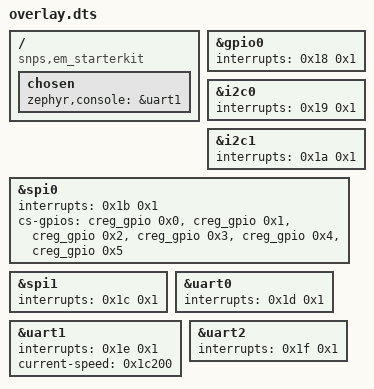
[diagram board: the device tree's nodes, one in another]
/ {
	compatible = "snps,em_starterkit", "snps,em_starterkit-em9d";
	chosen {
		zephyr,console = &uart1;
	};
};
&gpio0{
	interrupts = < 0x18 0x1 >;
};
&i2c0{
	interrupts = < 0x19 0x1 >;
};
&i2c1{
	interrupts = < 0x1a 0x1 >;
};
&spi0{
	interrupts = < 0x1b 0x1 >;
	cs-gpios = < &creg_gpio 0x0 0x0 >, < &creg_gpio 0x1 0x0 >, < &creg_gpio 0x2 0x0 >, < &creg_gpio 0x3 0x0 >, < &creg_gpio 0x4 0x0 >, < &creg_gpio 0x5 0x0 >;
};
&spi1{
	interrupts = < 0x1c 0x1 >;
};
&uart0{
	interrupts = < 0x1d 0x1 >;
};
&uart1{
	interrupts = < 0x1e 0x1 >;
	status = "okay";
	current-speed = < 0x1c200 >;
};
&uart2{
	interrupts = < 0x1f 0x1 >;
};
